# STM32H562 register map
File version: 0.1
CPU: CM33 r0p0, little endian, MPU, FPU, 4 interrupt priority bits
Registers are 32-bit, read-write, reset 0x0 unless marked. A register's access mark holds for its fields unless they carry their own. Offsets are from the block's base; [hi:lo] are bit positions; 'fields as' and 'values as' point back to an identical list.

## OCTOSPI — Octo-SPI interface
Base 0x47001400
Same registers: SEC_OCTOSPI 0x57001400
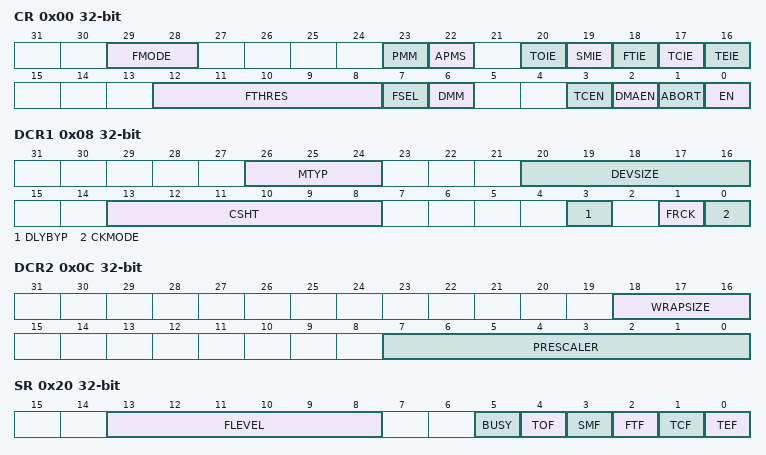
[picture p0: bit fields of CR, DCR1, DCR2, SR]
0x00 CR — OCTOSPI control register
  [29:28] FMODE — Functional mode This field defines the OCTOSPI functional mode of operation. If DMAEN = 1 already, then the DMA controller for the corresponding channel must be disabled before changing the FMODE[1:0] value. If FMODE[1:0] and FTHRES[4:0] are wrongly updated while DMAEN = 1, the DMA request signal automatically goes to inactive state.
  [23] PMM — Polling match mode This bit indicates which method must be used to determine a match during the Automatic status-polling mode.
  [22] APMS — Automatic status-polling mode stop This bit determines if the Automatic status-polling mode is stopped after a match.
  [20] TOIE — Timeout interrupt enable This bit enables the timeout interrupt.
  [19] SMIE — Status match interrupt enable This bit enables the status match interrupt.
  [18] FTIE — FIFO threshold interrupt enable This bit enables the FIFO threshold interrupt.
  [17] TCIE — Transfer complete interrupt enable This bit enables the transfer complete interrupt.
  [16] TEIE — Transfer error interrupt enable This bit enables the transfer error interrupt.
  [12:8] FTHRES — FIFO threshold level This field defines, in Indirect mode, the threshold number of bytes in the FIFO that causes the FIFO threshold flag FTF in OCTOSPI_SR, to be set. ... Note: If DMAEN = 1, the DMA controller for the corresponding channel must be disabled before changing the FTHRES[4:0] value.
  [7] FSEL — Flash select This bit selects the Flash memory to be addressed in Single-, Dual-, Quad-SPI mode in single-memory configuration (when DMM = 0). This bit is ignored when DMM = 1 or when Octal-SPI mode is selected.
  [6] DMM — Dual-memory configuration This bit activates the dual-memory configuration, where two external devices are used simultaneously to double the throughput and the capacity
  [3] TCEN — Timeout counter enable This bit is valid only when the Memory-mapped mode (FMODE[1:0] = 11) is selected. This bit enables the timeout counter.
  [2] DMAEN — DMA enable In Indirect mode, the DMA can be used to input or output data via OCTOSPI_DR. DMA transfers are initiated when FTF is set. Note: Resetting the DMAEN bit while a DMA transfer is ongoing, breaks the handshake with the DMA. Do not write this bit during DMA operation.
  [1] ABORT — Abort request This bit aborts the ongoing command sequence. It is automatically reset once the abort is completed. This bit stops the current transfer. Note: This bit is always read as 0.
  [0] EN — Enable This bit enables the OCTOSPI. Note: The DMA request can be aborted without having received the ACK in case this EN bit is cleared during the operation. In case this bit is set to 0 during a DMA transfer, the REQ signal to DMA returns to inactive state without waiting for the ACK signal from DMA to be active.
0x08 DCR1 — OCTOSPI device configuration register 1
  [26:24] MTYP — Memory type This bit indicates the type of memory to be supported. Note: In this mode, DQS signal polarity is inverted with respect to the memory clock signal. This is the default value and care must be taken to change MTYP[2:0] for memories different from Micron. Others: Reserved
  [20:16] DEVSIZE — Device size This field defines the size of the external device using the following formula: Number of bytes in device = 2[DEVSIZE+1]. DEVSIZE+1 is effectively the number of address bits required to address the external device. The device capacity can be up to 4 Gbytes (addressed using 32-bits) in Indirect mode, but the addressable space in Memory-mapped mode is limited to 256 Mbytes. In Regular-command protocol, if DMM = 1, DEVSIZE[4:0] indicates the total capacity of the two devices together.
  [13:8] CSHT — Chip-select high time CSHT + 1 defines the minimum number of CLK cycles where the chip-select (NCS) must remain high between commands issued to the external device. ...
  [3] DLYBYP — Delay block bypass
  [1] FRCK — Free running clock This bit configures the free running clock.
  [0] CKMODE — Mode 0/Mode 3 This bit indicates the level taken by the CLK between commands (when NCS = 1).
0x0C DCR2 — OCTOSPI device configuration register 2
  [18:16] WRAPSIZE — Wrap size This field indicates the wrap size to which the memory is configured. For memories which have a separate command for wrapped instructions, this field indicates the wrap-size associated with the command held in the OCTOSPI1_WPIR register. 110-111: Reserved
  [7:0] PRESCALER — Clock prescaler This field defines the scaler factor for generating the CLK based on the kernel clock (value + 1). 2: FCLK = FKERNEL/3 ... 255: FCLK = FKERNEL/256 For odd clock division factors, the CLK duty cycle is not 50 %. The clock signal remains low one cycle longer than it stays high.
0x10 DCR3 — OCTOSPI device configuration register 3
  [20:16] CSBOUND — NCS boundary This field enables the transaction boundary feature. When active, a minimum value of 3 is recommended. The NCS is released on each boundary of 2CSBOUND bytes. others: NCS boundary set to 2CSBOUND bytes
0x14 DCR4 — OCTOSPI device configuration register 4
  [31:0] REFRESH — Refresh rate This field enables the refresh rate feature. The NCS is released every REFRESH + 1 clock cycles for writes, and REFRESH + 4 clock cycles for reads. Note: These two values can be extended with few clock cycles when refresh occurs during a byte transmission in Single-, Dual- or Quad-SPI mode, because the byte transmission must be completed. others: Maximum communication length is set to REFRESH + 1 clock cycles.
0x20 SR ro — OCTOSPI status register
  [13:8] FLEVEL — FIFO level This field gives the number of valid bytes that are being held in the FIFO. FLEVEL = 0 when the FIFO is empty, and 32 when it is full. In Automatic status-polling mode, FLEVEL is zero.
  [5] BUSY — Busy This bit is set when an operation is ongoing. It is cleared automatically when the operation with the external device is finished and the FIFO is empty.
  [4] TOF — Timeout flag This bit is set when timeout occurs. It is cleared by writing 1 to CTOF.
  [3] SMF — Status match flag This bit is set in Automatic status-polling mode when the unmasked received data matches the corresponding bits in the match register (OCTOSPI_PSMAR). It is cleared by writing 1 to CSMF.
  [2] FTF — FIFO threshold flag In Indirect mode, this bit is set when the FIFO threshold has been reached, or if there is any data left in the FIFO after the reads from the external device are complete. It is cleared automatically as soon as the threshold condition is no longer true. In Automatic status-polling mode, this bit is set every time the status register is read, and the bit is cleared when the data register is read.
  [1] TCF — Transfer complete flag This bit is set in Indirect mode when the programmed number of data has been transferred or in any mode when the transfer has been aborted.It is cleared by writing 1 to CTCF.
  [0] TEF — Transfer error flag This bit is set in Indirect mode when an invalid address is being accessed in Indirect mode. It is cleared by writing 1 to CTEF.
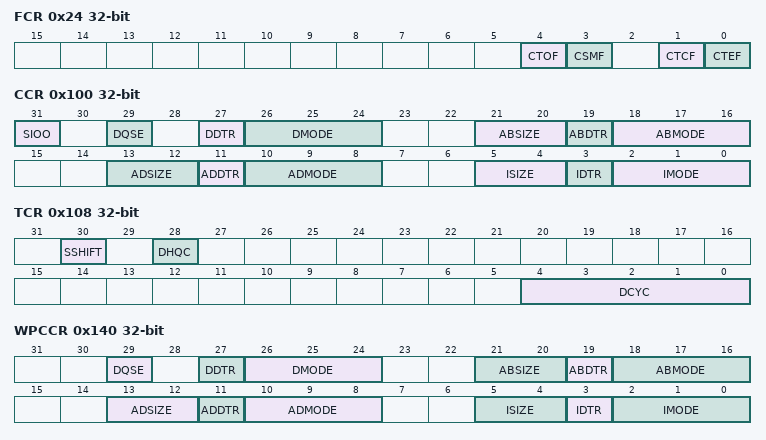
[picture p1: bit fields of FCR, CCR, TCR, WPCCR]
0x24 FCR wo — OCTOSPI flag clear register
  [4] CTOF — Clear timeout flag Writing 1 clears the TOF flag in the OCTOSPI_SR register.
  [3] CSMF — Clear status match flag Writing 1 clears the SMF flag in the OCTOSPI_SR register.
  [1] CTCF — Clear transfer complete flag Writing 1 clears the TCF flag in the OCTOSPI_SR register.
  [0] CTEF — Clear transfer error flag Writing 1 clears the TEF flag in the OCTOSPI_SR register.
0x40 DLR — OCTOSPI data length register
  [31:0] DL — [31: 0]: Data length Number of data to be retrieved (value+1) in Indirect and Automatic status-polling modes. A value not greater than three (indicating 4 bytes) must be used for Automatic status-polling mode. All 1’s in Indirect mode means undefined length, where OCTOSPI continues until the end of the memory, as defined by DEVSIZE. 0x0000_0000: 1 byte is to be transferred. 0x0000_0001: 2 bytes are to be transferred. 0x0000_0002: 3 bytes are to be transferred. 0x0000_0003: 4 bytes are to be transferred. ... 0xFFFF_FFFD: 4,294,967,294 (4G-2) bytes are to be transferred. 0xFFFF_FFFE: 4,294,967,295 (4G-1) bytes are to be transferred. 0xFFFF_FFFF: undefined length; all bytes, until the end of the external device, (as defined by DEVSIZE) are to be transferred. Continue reading indefinitely if DEVSIZE = 0x1F. DL[0] is stuck at 1 in dual-memory configuration (DMM = 1) even when 0 is written to this bit, thus assuring that each access transfers an even number of bytes. This field has no effect in Memory-mapped mode.
0x48 AR — OCTOSPI address register
  [31:0] ADDRESS — Address Address to be sent to the external device. In HyperBus protocol, this field must be even as this protocol is 16-bit word oriented. In dual-memory configuration, AR[0] is forced to 1. Writes to this field are ignored when BUSY = 1 or when FMODE = 11 (Memory-mapped mode).
0x50 DR — OCTOSPI data register
  [31:0] DATA — [31: 0]: Data Data to be sent/received to/from the external SPI device In Indirect-write mode, data written to this register is stored on the FIFO before it is sent to the external device during the data phase. If the FIFO is too full, a write operation is stalled until the FIFO has enough space to accept the amount of data being written. In Indirect-read mode, reading this register gives (via the FIFO) the data that was received from the external device. If the FIFO does not have as many bytes as requested by the read operation and if BUSY = 1, the read operation is stalled until enough data is present or until the transfer is complete, whichever happens first. In Automatic status-polling mode, this register contains the last data read from the external device (without masking). Word, half-word, and byte accesses to this register are supported. In Indirect-write mode, a byte write adds 1 byte to the FIFO, a half-word write 2 bytes, and a word write 4 bytes. Similarly, in Indirect-read mode, a byte read removes 1 byte from the FIFO, a halfword read 2 bytes, and a word read 4 bytes. Accesses in Indirect mode must be aligned to the bottom of this register: A byte read must read DATA[7:0] and a half-word read must read DATA[15:0].
0x80 PSMKR — OCTOSPI polling status mask register
  [31:0] MASK — Status mask Mask to be applied to the status bytes received in Automatic status-polling mode For bit n:
0x88 PSMAR — OCTOSPI polling status match register
  [31:0] MATCH — [31: 0]: Status match Value to be compared with the masked status register to get a match
0x90 PIR — OCTOSPI polling interval register
  [15:0] INTERVAL — [15: 0]: Polling interval Number of CLK cycle between a read during the Automatic status-polling phases
0x100 CCR — OCTOSPI communication configuration register
  [31] SIOO — Send instruction only once mode This bit has no effect when IMODE = 00 (see ).
  [29] DQSE — DQS enable This bit enables the data strobe management.
  [27] DDTR — Data double transfer rate This bit sets the DTR mode for the data phase.
  [26:24] DMODE — Data mode This field defines the data phase mode of operation. 101-111: Reserved
  [21:20] ABSIZE — Alternate bytes size This bit defines alternate bytes size.
  [19] ABDTR — Alternate bytes double transfer rate This bit sets the DTR mode for the alternate bytes phase. This field can be written only when BUSY = 0.
  [18:16] ABMODE — Alternate-byte mode This field defines the alternate-byte phase mode of operation. 101-111: Reserved
  [13:12] ADSIZE — Address size This field defines address size.
  [11] ADDTR — Address double transfer rate This bit sets the DTR mode for the address phase.
  [10:8] ADMODE — Address mode This field defines the address phase mode of operation. 101-111: Reserved
  [5:4] ISIZE — Instruction size This bit defines instruction size.
  [3] IDTR — Instruction double transfer rate This bit sets the DTR mode for the instruction phase.
  [2:0] IMODE — Instruction mode This field defines the instruction phase mode of operation. 101-111: Reserved
0x108 TCR — OCTOSPI timing configuration register
  [30] SSHIFT — Sample shift By default, the OCTOSPI samples data 1/2 of a CLK cycle after the data is driven by the external device. This bit allows the data to be sampled later in order to consider the external signal delays. The software must ensure that SSHIFT = 0 when the data phase is configured in DTR mode (when DDTR = 1.)
  [28] DHQC — Delay hold quarter cycle
  [4:0] DCYC — Number of dummy cycles This field defines the duration of the dummy phase. In both SDR and DTR modes, it specifies a number of CLK cycles (0-31). It is recommended to have at least six dummy cycles when using memories with DQS activated.
0x110 IR — OCTOSPI instruction register
  [31:0] INSTRUCTION — Instruction Instruction to be sent to the external SPI device
0x120 ABR — OCTOSPI alternate bytes register
  [31:0] ALTERNATE — [31: 0]: Alternate bytes Optional data to be sent to the external SPI device right after the address.
0x130 LPTR — OCTOSPI low-power timeout register
  [15:0] TIMEOUT — [15: 0]: Timeout period After each access in Memory-mapped mode, the OCTOSPI prefetches the subsequent bytes and hold them in the FIFO. This field indicates how many CLK cycles the OCTOSPI waits after the clock becomes inactive and until it raises the NCS, putting the external device in a lower-consumption state.
0x140 WPCCR — OCTOSPI wrap communication configuration register
  [29] DQSE — DQS enable This bit enables the data strobe management.
  [27] DDTR — Data double transfer rate This bit sets the DTR mode for the data phase.
  [26:24] DMODE — Data mode This field defines the data phase mode of operation. 101-111: Reserved
  [21:20] ABSIZE — Alternate bytes size This bit defines alternate bytes size.
  [19] ABDTR — Alternate bytes double transfer rate This bit sets the DTR mode for the alternate bytes phase.
  [18:16] ABMODE — Alternate-byte mode This field defines the alternate byte phase mode of operation. 101-111: Reserved
  [13:12] ADSIZE — Address size This field defines address size.
  [11] ADDTR — Address double transfer rate This bit sets the DTR mode for the address phase.
  [10:8] ADMODE — Address mode This field defines the address phase mode of operation. 101-111: Reserved
  [5:4] ISIZE — Instruction size This field defines instruction size.
  [3] IDTR — Instruction double transfer rate This bit sets the DTR mode for the instruction phase.
  [2:0] IMODE — Instruction mode This field defines the instruction phase mode of operation. 101-111: Reserved
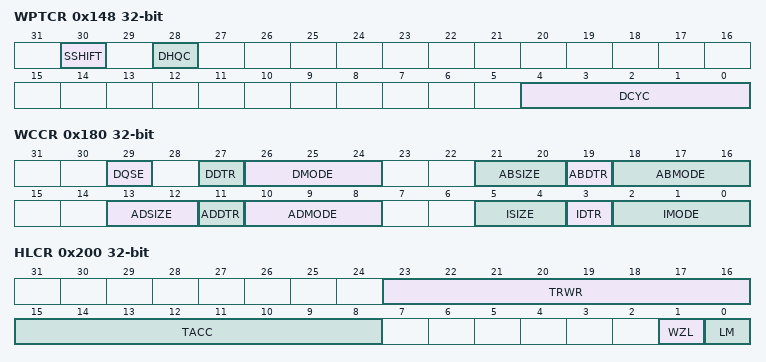
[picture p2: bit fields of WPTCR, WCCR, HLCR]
0x148 WPTCR — OCTOSPI wrap timing configuration register
  [30] SSHIFT — Sample shift By default, the OCTOSPI samples data 1/2 of a CLK cycle after the data is driven by the external device. This bit allows the data to be sampled later in order to consider the external signal delays. The firmware must assure that SSHIFT=0 when the data phase is configured in DTR mode (when DDTR = 1).
  [28] DHQC — Delay hold quarter cycle Add a quarter cycle delay on the outputs in DTR communication to match hold requirement.
  [4:0] DCYC — Number of dummy cycles This field defines the duration of the dummy phase. In both SDR and DTR modes, it specifies a number of CLK cycles (0-31). It is recommended to have at least 5 dummy cycles when using memories with DQS activated.
0x150 WPIR — OCTOSPI wrap instruction register
  [31:0] INSTRUCTION — [31: 0]: Instruction Instruction to be sent to the external SPI device
0x160 WPABR — OCTOSPI wrap alternate bytes register
  [31:0] ALTERNATE — [31: 0]: Alternate bytes Optional data to be sent to the external SPI device right after the address
0x180 WCCR — OCTOSPI write communication configuration register
  [29] DQSE — DQS enable This bit enables the data strobe management.
  [27] DDTR — data double transfer rate This bit sets the DTR mode for the data phase.
  [26:24] DMODE — Data mode This field defines the data phase mode of operation. 101-111: Reserved
  [21:20] ABSIZE — Alternate bytes size This field defines alternate bytes size:
  [19] ABDTR — Alternate bytes double transfer rate This bit sets the DTR mode for the alternate-bytes phase.
  [18:16] ABMODE — Alternate-byte mode This field defines the alternate-byte phase mode of operation. 101-111: Reserved
  [13:12] ADSIZE — Address size This field defines address size.
  [11] ADDTR — Address double transfer rate This bit sets the DTR mode for the address phase.
  [10:8] ADMODE — Address mode This field defines the address phase mode of operation. 101-111: Reserved
  [5:4] ISIZE — Instruction size This bit defines instruction size:
  [3] IDTR — Instruction double transfer rate This bit sets the DTR mode for the instruction phase.
  [2:0] IMODE — Instruction mode This field defines the instruction phase mode of operation. 101-111: Reserved
0x188 WTCR — OCTOSPI write timing configuration register
  [4:0] DCYC — Number of dummy cycles This field defines the duration of the dummy phase. In both SDR and DTR modes, it specifies a number of CLK cycles (0-31). It is recommended to have at least 5 dummy cycles when using memories with DQS activated.
0x190 WIR — OCTOSPI write instruction register
  fields as IR
0x1A0 WABR — OCTOSPI write alternate bytes register
  fields as WPABR
0x200 HLCR — OCTOSPI HyperBus latency configuration register
  [23:16] TRWR — Read write recovery time Device read write recovery time expressed in number of communication clock cycles
  [15:8] TACC — [7: 0]: Access time Device access time expressed in number of communication clock cycles
  [1] WZL — Write zero latency This bit enables zero latency on write operations.
  [0] LM — Latency mode This bit selects the Latency mode.
